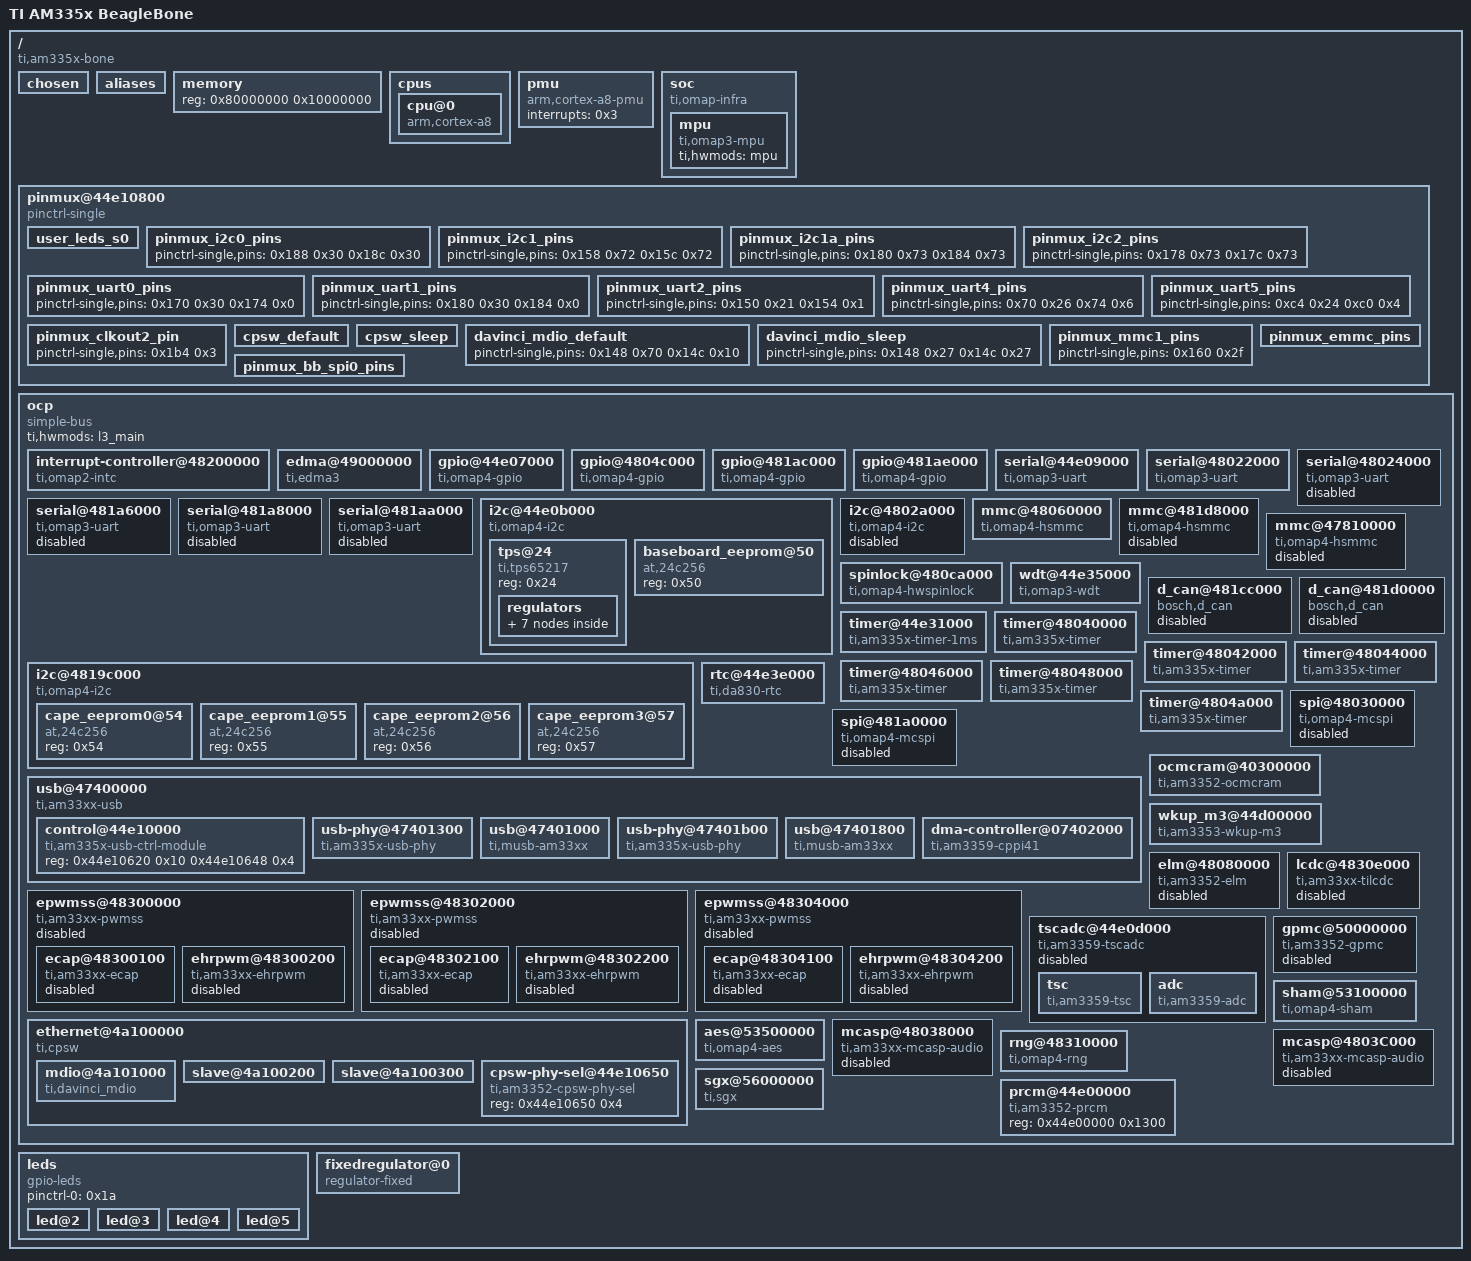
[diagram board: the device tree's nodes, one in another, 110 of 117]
/dts-v1/;

/ {
	#address-cells = <0x1>;
	#size-cells = <0x1>;
	compatible = "ti,am335x-bone", "ti,am33xx";
	interrupt-parent = <0x1>;
	model = "TI AM335x BeagleBone";

	chosen {
	};

	aliases {
		i2c0 = "/ocp/i2c@44e0b000";
		i2c1 = "/ocp/i2c@4802a000";
		i2c2 = "/ocp/i2c@4819c000";
		serial0 = "/ocp/serial@44e09000";
		serial1 = "/ocp/serial@48022000";
		serial2 = "/ocp/serial@48024000";
		serial3 = "/ocp/serial@481a6000";
		serial4 = "/ocp/serial@481a8000";
		serial5 = "/ocp/serial@481aa000";
		d_can0 = "/ocp/d_can@481cc000";
		d_can1 = "/ocp/d_can@481d0000";
		usb0 = "/ocp/usb@47400000/usb@47401000";
		usb1 = "/ocp/usb@47400000/usb@47401800";
		phy0 = "/ocp/usb@47400000/usb-phy@47401300";
		phy1 = "/ocp/usb@47400000/usb-phy@47401b00";
		ethernet0 = "/ocp/ethernet@4a100000/slave@4a100200";
		ethernet1 = "/ocp/ethernet@4a100000/slave@4a100300";
	};

	memory {
		device_type = "memory";
		reg = <0x80000000 0x10000000>;
	};

	cpus {
		#address-cells = <0x1>;
		#size-cells = <0x0>;

		cpu@0 {
			compatible = "arm,cortex-a8";
			device_type = "cpu";
			reg = <0x0>;
			operating-points = <0xafc80 0x139b88 0x927c0 0x12b128 0x7a120 0x112a88 0x43238 0x112a88>;
			voltage-tolerance = <0x2>;
			clock-latency = <0x493e0>;
			cpu0-supply = <0x2>;
		};
	};

	pmu {
		compatible = "arm,cortex-a8-pmu";
		interrupts = <0x3>;
	};

	soc {
		compatible = "ti,omap-infra";

		mpu {
			compatible = "ti,omap3-mpu";
			ti,hwmods = "mpu";
		};
	};

	pinmux@44e10800 {
		compatible = "pinctrl-single";
		reg = <0x44e10800 0x238>;
		#address-cells = <0x1>;
		#size-cells = <0x0>;
		pinctrl-single,register-width = <0x20>;
		pinctrl-single,function-mask = <0x7f>;
		pinctrl-names = "default";
		pinctrl-0 = <0x3>;

		user_leds_s0 {
			pinctrl-single,pins = <0x54 0x7 0x58 0x17 0x5c 0x7 0x60 0x17>;
			linux,phandle = <0x1a>;
			phandle = <0x1a>;
		};

		pinmux_i2c0_pins {
			pinctrl-single,pins = <0x188 0x30 0x18c 0x30>;
			linux,phandle = <0x9>;
			phandle = <0x9>;
		};

		pinmux_i2c1_pins {
			pinctrl-single,pins = <0x158 0x72 0x15c 0x72>;
			linux,phandle = <0xa>;
			phandle = <0xa>;
		};

		pinmux_i2c1a_pins {
			pinctrl-single,pins = <0x180 0x73 0x184 0x73>;
		};

		pinmux_i2c2_pins {
			pinctrl-single,pins = <0x178 0x73 0x17c 0x73>;
			linux,phandle = <0xb>;
			phandle = <0xb>;
		};

		pinmux_uart0_pins {
			pinctrl-single,pins = <0x170 0x30 0x174 0x0>;
			linux,phandle = <0x4>;
			phandle = <0x4>;
		};

		pinmux_uart1_pins {
			pinctrl-single,pins = <0x180 0x30 0x184 0x0>;
			linux,phandle = <0x5>;
			phandle = <0x5>;
		};

		pinmux_uart2_pins {
			pinctrl-single,pins = <0x150 0x21 0x154 0x1>;
			linux,phandle = <0x6>;
			phandle = <0x6>;
		};

		pinmux_uart4_pins {
			pinctrl-single,pins = <0x70 0x26 0x74 0x6>;
			linux,phandle = <0x7>;
			phandle = <0x7>;
		};

		pinmux_uart5_pins {
			pinctrl-single,pins = <0xc4 0x24 0xc0 0x4>;
			linux,phandle = <0x8>;
			phandle = <0x8>;
		};

		pinmux_clkout2_pin {
			pinctrl-single,pins = <0x1b4 0x3>;
			linux,phandle = <0x3>;
			phandle = <0x3>;
		};

		cpsw_default {
			pinctrl-single,pins = <0x110 0x30 0x114 0x0 0x118 0x30 0x11c 0x0 0x120 0x0 0x124 0x0 0x128 0x0 0x12c 0x30 0x130 0x30 0x134 0x30 0x138 0x30 0x13c 0x30 0x140 0x30>;
			linux,phandle = <0x14>;
			phandle = <0x14>;
		};

		cpsw_sleep {
			pinctrl-single,pins = <0x110 0x27 0x114 0x27 0x118 0x27 0x11c 0x27 0x120 0x27 0x124 0x27 0x128 0x27 0x12c 0x27 0x130 0x27 0x134 0x27 0x138 0x27 0x13c 0x27 0x140 0x27>;
			linux,phandle = <0x15>;
			phandle = <0x15>;
		};

		davinci_mdio_default {
			pinctrl-single,pins = <0x148 0x70 0x14c 0x10>;
			linux,phandle = <0x16>;
			phandle = <0x16>;
		};

		davinci_mdio_sleep {
			pinctrl-single,pins = <0x148 0x27 0x14c 0x27>;
			linux,phandle = <0x17>;
			phandle = <0x17>;
		};

		pinmux_mmc1_pins {
			pinctrl-single,pins = <0x160 0x2f>;
			linux,phandle = <0xd>;
			phandle = <0xd>;
		};

		pinmux_emmc_pins {
			pinctrl-single,pins = <0x80 0x32 0x84 0x32 0x0 0x31 0x4 0x31 0x8 0x31 0xc 0x31 0x10 0x31 0x14 0x31 0x18 0x31 0x1c 0x31>;
		};

		pinmux_bb_spi0_pins {
			pinctrl-single,pins = <0x150 0x30 0x154 0x30 0x158 0x10 0x15c 0x10>;
		};
	};

	ocp {
		compatible = "simple-bus";
		#address-cells = <0x1>;
		#size-cells = <0x1>;
		ranges;
		ti,hwmods = "l3_main";

		interrupt-controller@48200000 {
			compatible = "ti,omap2-intc";
			interrupt-controller;
			#interrupt-cells = <0x1>;
			ti,intc-size = <0x80>;
			reg = <0x48200000 0x1000>;
			linux,phandle = <0x1>;
			phandle = <0x1>;
		};

		edma@49000000 {
			compatible = "ti,edma3";
			ti,hwmods = "tpcc", "tptc0", "tptc1", "tptc2";
			reg = <0x49000000 0x10000 0x44e10f90 0x10>;
			interrupts = <0xc 0xd 0xe>;
			#dma-cells = <0x1>;
			dma-channels = <0x40>;
			ti,edma-regions = <0x4>;
			ti,edma-slots = <0x100>;
			linux,phandle = <0xc>;
			phandle = <0xc>;
		};

		gpio@44e07000 {
			compatible = "ti,omap4-gpio";
			ti,hwmods = "gpio1";
			gpio-controller;
			#gpio-cells = <0x2>;
			interrupt-controller;
			#interrupt-cells = <0x2>;
			reg = <0x44e07000 0x1000>;
			interrupts = <0x60>;
			linux,phandle = <0xe>;
			phandle = <0xe>;
		};

		gpio@4804c000 {
			compatible = "ti,omap4-gpio";
			ti,hwmods = "gpio2";
			gpio-controller;
			#gpio-cells = <0x2>;
			interrupt-controller;
			#interrupt-cells = <0x2>;
			reg = <0x4804c000 0x1000>;
			interrupts = <0x62>;
			linux,phandle = <0x1b>;
			phandle = <0x1b>;
		};

		gpio@481ac000 {
			compatible = "ti,omap4-gpio";
			ti,hwmods = "gpio3";
			gpio-controller;
			#gpio-cells = <0x2>;
			interrupt-controller;
			#interrupt-cells = <0x2>;
			reg = <0x481ac000 0x1000>;
			interrupts = <0x20>;
		};

		gpio@481ae000 {
			compatible = "ti,omap4-gpio";
			ti,hwmods = "gpio4";
			gpio-controller;
			#gpio-cells = <0x2>;
			interrupt-controller;
			#interrupt-cells = <0x2>;
			reg = <0x481ae000 0x1000>;
			interrupts = <0x3e>;
		};

		serial@44e09000 {
			compatible = "ti,omap3-uart";
			ti,hwmods = "uart1";
			clock-frequency = <0x2dc6c00>;
			reg = <0x44e09000 0x2000>;
			interrupts = <0x48>;
			status = "okay";
			pinctrl-names = "default";
			pinctrl-0 = <0x4>;
		};

		serial@48022000 {
			compatible = "ti,omap3-uart";
			ti,hwmods = "uart2";
			clock-frequency = <0x2dc6c00>;
			reg = <0x48022000 0x2000>;
			interrupts = <0x49>;
			status = "okay";
			pinctrl-names = "default";
			pinctrl-0 = <0x5>;
		};

		serial@48024000 {
			compatible = "ti,omap3-uart";
			ti,hwmods = "uart3";
			clock-frequency = <0x2dc6c00>;
			reg = <0x48024000 0x2000>;
			interrupts = <0x4a>;
			status = "disabled";
			//status = "okay";
			//pinctrl-names = "default";
			//pinctrl-0 = <0x6>;
		};

		serial@481a6000 {
			compatible = "ti,omap3-uart";
			ti,hwmods = "uart4";
			clock-frequency = <0x2dc6c00>;
			reg = <0x481a6000 0x2000>;
			interrupts = <0x2c>;
			status = "disabled";
		};

		serial@481a8000 {
			compatible = "ti,omap3-uart";
			ti,hwmods = "uart5";
			clock-frequency = <0x2dc6c00>;
			reg = <0x481a8000 0x2000>;
			interrupts = <0x2d>;
			status = "disabled";
			//status = "okay";
			//pinctrl-names = "default";
			//pinctrl-0 = <0x7>;
		};

		serial@481aa000 {
			compatible = "ti,omap3-uart";
			ti,hwmods = "uart6";
			clock-frequency = <0x2dc6c00>;
			reg = <0x481aa000 0x2000>;
			interrupts = <0x2e>;
			status = "disabled";
			//status = "okay";
			//pinctrl-names = "default";
			//pinctrl-0 = <0x8>;
		};

		i2c@44e0b000 {
			compatible = "ti,omap4-i2c";
			#address-cells = <0x1>;
			#size-cells = <0x0>;
			ti,hwmods = "i2c1";
			reg = <0x44e0b000 0x1000>;
			interrupts = <0x46>;
			status = "okay";
			pinctrl-names = "default";
			pinctrl-0 = <0x9>;
			clock-frequency = <0x61a80>;

			tps@24 {
				reg = <0x24>;
				compatible = "ti,tps65217";

				regulators {
					#address-cells = <0x1>;
					#size-cells = <0x0>;

					regulator@0 {
						reg = <0x0>;
						regulator-compatible = "dcdc1";
						regulator-always-on;
					};

					regulator@1 {
						reg = <0x1>;
						regulator-compatible = "dcdc2";
						regulator-name = "vdd_mpu";
						regulator-min-microvolt = <0xe1d48>;
						regulator-max-microvolt = <0x1437c8>;
						regulator-boot-on;
						regulator-always-on;
						linux,phandle = <0x2>;
						phandle = <0x2>;
					};

					regulator@2 {
						reg = <0x2>;
						regulator-compatible = "dcdc3";
						regulator-name = "vdd_core";
						regulator-min-microvolt = <0xe1d48>;
						regulator-max-microvolt = <0x118c30>;
						regulator-boot-on;
						regulator-always-on;
					};

					regulator@3 {
						reg = <0x3>;
						regulator-compatible = "ldo1";
						regulator-always-on;
					};

					regulator@4 {
						reg = <0x4>;
						regulator-compatible = "ldo2";
						regulator-always-on;
					};

					regulator@5 {
						reg = <0x5>;
						regulator-compatible = "ldo3";
						regulator-always-on;
						regulator-min-microvolt = <0x1b7740>;
						regulator-max-microvolt = <0x325aa0>;
						linux,phandle = <0xf>;
						phandle = <0xf>;
					};

					regulator@6 {
						reg = <0x6>;
						regulator-compatible = "ldo4";
						regulator-always-on;
					};
				};
			};

			baseboard_eeprom@50 {
				compatible = "at,24c256";
				reg = <0x50>;
			};
		};

		i2c@4802a000 {
			compatible = "ti,omap4-i2c";
			#address-cells = <0x1>;
			#size-cells = <0x0>;
			ti,hwmods = "i2c2";
			reg = <0x4802a000 0x1000>;
			interrupts = <0x47>;
			status = "disabled";
			//status = "okay";
			//pinctrl-names = "default";
			//pinctrl-0 = <0xa>;
			//clock-frequency = <0x186a0>;
		};

		i2c@4819c000 {
			compatible = "ti,omap4-i2c";
			#address-cells = <0x1>;
			#size-cells = <0x0>;
			ti,hwmods = "i2c3";
			reg = <0x4819c000 0x1000>;
			interrupts = <0x1e>;
			status = "okay";
			pinctrl-names = "default";
			pinctrl-0 = <0xb>;
			clock-frequency = <0x186a0>;

			cape_eeprom0@54 {
				compatible = "at,24c256";
				reg = <0x54>;
			};

			cape_eeprom1@55 {
				compatible = "at,24c256";
				reg = <0x55>;
			};

			cape_eeprom2@56 {
				compatible = "at,24c256";
				reg = <0x56>;
			};

			cape_eeprom3@57 {
				compatible = "at,24c256";
				reg = <0x57>;
			};
		};

		mmc@48060000 {
			compatible = "ti,omap4-hsmmc";
			ti,hwmods = "mmc1";
			ti,dual-volt;
			ti,needs-special-reset;
			ti,needs-special-hs-handling;
			dmas = <0xc 0x18 0xc 0x19>;
			dma-names = "tx", "rx";
			interrupts = <0x40>;
			interrupt-parent = <0x1>;
			reg = <0x48060000 0x1000>;
			status = "okay";
			bus-width = <0x4>;
			pinctrl-names = "default";
			pinctrl-0 = <0xd>;
			cd-gpios = <0xe 0x6 0x0>;
			cd-inverted;
			vmmc-supply = <0xf>;
		};

		mmc@481d8000 {
			compatible = "ti,omap4-hsmmc";
			ti,hwmods = "mmc2";
			ti,needs-special-reset;
			dmas = <0xc 0x2 0xc 0x3>;
			dma-names = "tx", "rx";
			interrupts = <0x1c>;
			interrupt-parent = <0x1>;
			reg = <0x481d8000 0x1000>;
			status = "disabled";
		};

		mmc@47810000 {
			compatible = "ti,omap4-hsmmc";
			ti,hwmods = "mmc3";
			ti,needs-special-reset;
			interrupts = <0x1d>;
			interrupt-parent = <0x1>;
			reg = <0x47810000 0x1000>;
			status = "disabled";
		};

		spinlock@480ca000 {
			compatible = "ti,omap4-hwspinlock";
			reg = <0x480ca000 0x1000>;
			ti,hwmods = "spinlock";
		};

		wdt@44e35000 {
			compatible = "ti,omap3-wdt";
			ti,hwmods = "wd_timer2";
			reg = <0x44e35000 0x1000>;
			interrupts = <0x5b>;
		};

		d_can@481cc000 {
			compatible = "bosch,d_can";
			ti,hwmods = "d_can0";
			reg = <0x481cc000 0x2000 0x44e10644 0x4>;
			interrupts = <0x34>;
			status = "disabled";
		};

		d_can@481d0000 {
			compatible = "bosch,d_can";
			ti,hwmods = "d_can1";
			reg = <0x481d0000 0x2000 0x44e10644 0x4>;
			interrupts = <0x37>;
			status = "disabled";
		};

		timer@44e31000 {
			compatible = "ti,am335x-timer-1ms";
			reg = <0x44e31000 0x400>;
			interrupts = <0x43>;
			ti,hwmods = "timer1";
			ti,timer-alwon;
		};

		timer@48040000 {
			compatible = "ti,am335x-timer";
			reg = <0x48040000 0x400>;
			interrupts = <0x44>;
			ti,hwmods = "timer2";
		};

		timer@48042000 {
			compatible = "ti,am335x-timer";
			reg = <0x48042000 0x400>;
			interrupts = <0x45>;
			ti,hwmods = "timer3";
		};

		timer@48044000 {
			compatible = "ti,am335x-timer";
			reg = <0x48044000 0x400>;
			interrupts = <0x5c>;
			ti,hwmods = "timer4";
			ti,timer-pwm;
		};

		timer@48046000 {
			compatible = "ti,am335x-timer";
			reg = <0x48046000 0x400>;
			interrupts = <0x5d>;
			ti,hwmods = "timer5";
			ti,timer-pwm;
		};

		timer@48048000 {
			compatible = "ti,am335x-timer";
			reg = <0x48048000 0x400>;
			interrupts = <0x5e>;
			ti,hwmods = "timer6";
			ti,timer-pwm;
		};

		timer@4804a000 {
			compatible = "ti,am335x-timer";
			reg = <0x4804a000 0x400>;
			interrupts = <0x5f>;
			ti,hwmods = "timer7";
			ti,timer-pwm;
		};

		rtc@44e3e000 {
			compatible = "ti,da830-rtc";
			reg = <0x44e3e000 0x1000>;
			interrupts = <0x4b 0x4c>;
			ti,hwmods = "rtc";
		};

		spi@48030000 {
			compatible = "ti,omap4-mcspi";
			#address-cells = <0x1>;
			#size-cells = <0x0>;
			reg = <0x48030000 0x400>;
			interrupts = <0x41>;
			ti,spi-num-cs = <0x2>;
			ti,hwmods = "spi0";
			dmas = <0xc 0x10 0xc 0x11 0xc 0x12 0xc 0x13>;
			dma-names = "tx0", "rx0", "tx1", "rx1";
			status = "disabled";
		};

		spi@481a0000 {
			compatible = "ti,omap4-mcspi";
			#address-cells = <0x1>;
			#size-cells = <0x0>;
			reg = <0x481a0000 0x400>;
			interrupts = <0x7d>;
			ti,spi-num-cs = <0x2>;
			ti,hwmods = "spi1";
			dmas = <0xc 0x2a 0xc 0x2b 0xc 0x2c 0xc 0x2d>;
			dma-names = "tx0", "rx0", "tx1", "rx1";
			status = "disabled";
		};

		usb@47400000 {
			compatible = "ti,am33xx-usb";
			reg = <0x47400000 0x1000>;
			ranges;
			#address-cells = <0x1>;
			#size-cells = <0x1>;
			ti,hwmods = "usb_otg_hs";
			status = "okay";

			control@44e10000 {
				compatible = "ti,am335x-usb-ctrl-module";
				reg = <0x44e10620 0x10 0x44e10648 0x4>;
				reg-names = "phy_ctrl", "wakeup";
				status = "okay";
				linux,phandle = <0x10>;
				phandle = <0x10>;
			};

			usb-phy@47401300 {
				compatible = "ti,am335x-usb-phy";
				reg = <0x47401300 0x100>;
				reg-names = "phy";
				status = "okay";
				ti,ctrl_mod = <0x10>;
				linux,phandle = <0x11>;
				phandle = <0x11>;
			};

			usb@47401000 {
				compatible = "ti,musb-am33xx";
				status = "okay";
				reg = <0x47401400 0x400 0x47401000 0x200>;
				reg-names = "mc", "control";
				interrupts = <0x12>;
				interrupt-names = "mc";
				dr_mode = "otg";
				mentor,multipoint = <0x1>;
				mentor,num-eps = <0x10>;
				mentor,ram-bits = <0xc>;
				mentor,power = <0x1f4>;
				phys = <0x11>;
				dmas = <0x12 0x0 0x0 0x12 0x1 0x0 0x12 0x2 0x0 0x12 0x3 0x0 0x12 0x4 0x0 0x12 0x5 0x0 0x12 0x6 0x0 0x12 0x7 0x0 0x12 0x8 0x0 0x12 0x9 0x0 0x12 0xa 0x0 0x12 0xb 0x0 0x12 0xc 0x0 0x12 0xd 0x0 0x12 0xe 0x0 0x12 0x0 0x1 0x12 0x1 0x1 0x12 0x2 0x1 0x12 0x3 0x1 0x12 0x4 0x1 0x12 0x5 0x1 0x12 0x6 0x1 0x12 0x7 0x1 0x12 0x8 0x1 0x12 0x9 0x1 0x12 0xa 0x1 0x12 0xb 0x1 0x12 0xc 0x1 0x12 0xd 0x1 0x12 0xe 0x1>;
				dma-names = "rx1", "rx2", "rx3", "rx4", "rx5", "rx6", "rx7", "rx8", "rx9", "rx10", "rx11", "rx12", "rx13", "rx14", "rx15", "tx1", "tx2", "tx3", "tx4", "tx5", "tx6", "tx7", "tx8", "tx9", "tx10", "tx11", "tx12", "tx13", "tx14", "tx15";
			};

			usb-phy@47401b00 {
				compatible = "ti,am335x-usb-phy";
				reg = <0x47401b00 0x100>;
				reg-names = "phy";
				status = "okay";
				ti,ctrl_mod = <0x10>;
				linux,phandle = <0x13>;
				phandle = <0x13>;
			};

			usb@47401800 {
				compatible = "ti,musb-am33xx";
				status = "okay";
				reg = <0x47401c00 0x400 0x47401800 0x200>;
				reg-names = "mc", "control";
				interrupts = <0x13>;
				interrupt-names = "mc";
				dr_mode = "host";
				mentor,multipoint = <0x1>;
				mentor,num-eps = <0x10>;
				mentor,ram-bits = <0xc>;
				mentor,power = <0x1f4>;
				phys = <0x13>;
				dmas = <0x12 0xf 0x0 0x12 0x10 0x0 0x12 0x11 0x0 0x12 0x12 0x0 0x12 0x13 0x0 0x12 0x14 0x0 0x12 0x15 0x0 0x12 0x16 0x0 0x12 0x17 0x0 0x12 0x18 0x0 0x12 0x19 0x0 0x12 0x1a 0x0 0x12 0x1b 0x0 0x12 0x1c 0x0 0x12 0x1d 0x0 0x12 0xf 0x1 0x12 0x10 0x1 0x12 0x11 0x1 0x12 0x12 0x1 0x12 0x13 0x1 0x12 0x14 0x1 0x12 0x15 0x1 0x12 0x16 0x1 0x12 0x17 0x1 0x12 0x18 0x1 0x12 0x19 0x1 0x12 0x1a 0x1 0x12 0x1b 0x1 0x12 0x1c 0x1 0x12 0x1d 0x1>;
				dma-names = "rx1", "rx2", "rx3", "rx4", "rx5", "rx6", "rx7", "rx8", "rx9", "rx10", "rx11", "rx12", "rx13", "rx14", "rx15", "tx1", "tx2", "tx3", "tx4", "tx5", "tx6", "tx7", "tx8", "tx9", "tx10", "tx11", "tx12", "tx13", "tx14", "tx15";
			};

			dma-controller@07402000 {
				compatible = "ti,am3359-cppi41";
				reg = <0x47400000 0x1000 0x47402000 0x1000 0x47403000 0x1000 0x47404000 0x4000>;
				reg-names = "glue", "controller", "scheduler", "queuemgr";
				interrupts = <0x11>;
				interrupt-names = "glue";
				#dma-cells = <0x2>;
				#dma-channels = <0x1e>;
				#dma-requests = <0x100>;
				status = "okay";
				linux,phandle = <0x12>;
				phandle = <0x12>;
			};
		};

		epwmss@48300000 {
			compatible = "ti,am33xx-pwmss";
			reg = <0x48300000 0x10>;
			ti,hwmods = "epwmss0";
			#address-cells = <0x1>;
			#size-cells = <0x1>;
			status = "disabled";
			ranges = <0x48300100 0x48300100 0x80 0x48300180 0x48300180 0x80 0x48300200 0x48300200 0x80>;

			ecap@48300100 {
				compatible = "ti,am33xx-ecap";
				#pwm-cells = <0x3>;
				reg = <0x48300100 0x80>;
				ti,hwmods = "ecap0";
				status = "disabled";
			};

			ehrpwm@48300200 {
				compatible = "ti,am33xx-ehrpwm";
				#pwm-cells = <0x3>;
				reg = <0x48300200 0x80>;
				ti,hwmods = "ehrpwm0";
				status = "disabled";
			};
		};

		epwmss@48302000 {
			compatible = "ti,am33xx-pwmss";
			reg = <0x48302000 0x10>;
			ti,hwmods = "epwmss1";
			#address-cells = <0x1>;
			#size-cells = <0x1>;
			status = "disabled";
			ranges = <0x48302100 0x48302100 0x80 0x48302180 0x48302180 0x80 0x48302200 0x48302200 0x80>;

			ecap@48302100 {
				compatible = "ti,am33xx-ecap";
				#pwm-cells = <0x3>;
				reg = <0x48302100 0x80>;
				ti,hwmods = "ecap1";
				status = "disabled";
			};

			ehrpwm@48302200 {
				compatible = "ti,am33xx-ehrpwm";
				#pwm-cells = <0x3>;
				reg = <0x48302200 0x80>;
				ti,hwmods = "ehrpwm1";
				status = "disabled";
			};
		};

		epwmss@48304000 {
			compatible = "ti,am33xx-pwmss";
			reg = <0x48304000 0x10>;
			ti,hwmods = "epwmss2";
			#address-cells = <0x1>;
			#size-cells = <0x1>;
			status = "disabled";
			ranges = <0x48304100 0x48304100 0x80 0x48304180 0x48304180 0x80 0x48304200 0x48304200 0x80>;

			ecap@48304100 {
				compatible = "ti,am33xx-ecap";
				#pwm-cells = <0x3>;
				reg = <0x48304100 0x80>;
				ti,hwmods = "ecap2";
				status = "disabled";
			};

			ehrpwm@48304200 {
				compatible = "ti,am33xx-ehrpwm";
				#pwm-cells = <0x3>;
				reg = <0x48304200 0x80>;
				ti,hwmods = "ehrpwm2";
				status = "disabled";
			};
		};

		ethernet@4a100000 {
			compatible = "ti,cpsw";
			ti,hwmods = "cpgmac0";
			cpdma_channels = <0x8>;
			ale_entries = <0x400>;
			bd_ram_size = <0x2000>;
			no_bd_ram = <0x0>;
			rx_descs = <0x40>;
			mac_control = <0x20>;
			slaves = <0x2>;
			active_slave = <0x0>;
			cpts_clock_mult = <0x80000000>;
			cpts_clock_shift = <0x1d>;
			reg = <0x4a100000 0x800 0x4a101200 0x100>;
			#address-cells = <0x1>;
			#size-cells = <0x1>;
			interrupt-parent = <0x1>;
			interrupts = <0x28 0x29 0x2a 0x2b>;
			ranges;
			pinctrl-names = "default", "sleep";
			pinctrl-0 = <0x14>;
			pinctrl-1 = <0x15>;

			mdio@4a101000 {
				compatible = "ti,davinci_mdio";
				#address-cells = <0x1>;
				#size-cells = <0x0>;
				ti,hwmods = "davinci_mdio";
				bus_freq = <0xf4240>;
				reg = <0x4a101000 0x100>;
				pinctrl-names = "default", "sleep";
				pinctrl-0 = <0x16>;
				pinctrl-1 = <0x17>;
				linux,phandle = <0x18>;
				phandle = <0x18>;
			};

			slave@4a100200 {
				mac-address = [00 00 00 00 00 00];
				phy_id = <0x18 0x0>;
				phy-mode = "mii";
			};

			slave@4a100300 {
				mac-address = [00 00 00 00 00 00];
				phy_id = <0x18 0x1>;
				phy-mode = "mii";
			};

			cpsw-phy-sel@44e10650 {
				compatible = "ti,am3352-cpsw-phy-sel";
				reg = <0x44e10650 0x4>;
				reg-names = "gmii-sel";
			};
		};

		ocmcram@40300000 {
			compatible = "ti,am3352-ocmcram";
			reg = <0x40300000 0x10000>;
			ti,hwmods = "ocmcram";
		};

		wkup_m3@44d00000 {
			compatible = "ti,am3353-wkup-m3";
			reg = <0x44d00000 0x4000 0x44d80000 0x2000>;
			ti,hwmods = "wkup_m3";
			ti,no-reset-on-init;
		};

		elm@48080000 {
			compatible = "ti,am3352-elm";
			reg = <0x48080000 0x2000>;
			interrupts = <0x4>;
			ti,hwmods = "elm";
			status = "disabled";
		};

		lcdc@4830e000 {
			compatible = "ti,am33xx-tilcdc";
			reg = <0x4830e000 0x1000>;
			interrupt-parent = <0x1>;
			interrupts = <0x24>;
			ti,hwmods = "lcdc";
			status = "disabled";
		};

		tscadc@44e0d000 {
			compatible = "ti,am3359-tscadc";
			reg = <0x44e0d000 0x1000>;
			interrupt-parent = <0x1>;
			interrupts = <0x10>;
			ti,hwmods = "adc_tsc";
			status = "disabled";

			tsc {
				compatible = "ti,am3359-tsc";
			};

			adc {
				#io-channel-cells = <0x1>;
				compatible = "ti,am3359-adc";
			};
		};

		gpmc@50000000 {
			compatible = "ti,am3352-gpmc";
			ti,hwmods = "gpmc";
			ti,no-idle-on-init;
			reg = <0x50000000 0x2000>;
			interrupts = <0x64>;
			gpmc,num-cs = <0x7>;
			gpmc,num-waitpins = <0x2>;
			#address-cells = <0x2>;
			#size-cells = <0x1>;
			status = "disabled";
		};

		sham@53100000 {
			compatible = "ti,omap4-sham";
			ti,hwmods = "sham";
			reg = <0x53100000 0x200>;
			interrupts = <0x6d>;
			dmas = <0xc 0x24>;
			dma-names = "rx";
			status = "okay";
		};

		aes@53500000 {
			compatible = "ti,omap4-aes";
			ti,hwmods = "aes";
			reg = <0x53500000 0xa0>;
			interrupts = <0x67>;
			dmas = <0xc 0x6 0xc 0x5>;
			dma-names = "tx", "rx";
			status = "okay";
		};

		mcasp@48038000 {
			compatible = "ti,am33xx-mcasp-audio";
			ti,hwmods = "mcasp0";
			reg = <0x48038000 0x2000 0x46000000 0x400000>;
			reg-names = "mpu", "dat";
			interrupts = <0x50 0x51>;
			interrupts-names = "tx", "rx";
			status = "disabled";
			dmas = <0xc 0x8 0xc 0x9>;
			dma-names = "tx", "rx";
		};

		mcasp@4803C000 {
			compatible = "ti,am33xx-mcasp-audio";
			ti,hwmods = "mcasp1";
			reg = <0x4803c000 0x2000 0x46400000 0x400000>;
			reg-names = "mpu", "dat";
			interrupts = <0x52 0x53>;
			interrupts-names = "tx", "rx";
			status = "disabled";
			dmas = <0xc 0xa 0xc 0xb>;
			dma-names = "tx", "rx";
		};

		rng@48310000 {
			compatible = "ti,omap4-rng";
			ti,hwmods = "rng";
			reg = <0x48310000 0x2000>;
			interrupts = <0x6f>;
		};

		prcm@44e00000 {
			compatible = "ti,am3352-prcm";
			reg = <0x44e00000 0x1300>;
			#reset-cells = <0x1>;
			linux,phandle = <0x19>;
			phandle = <0x19>;
		};

		sgx@56000000 {
			compatible = "ti,sgx";
			ti,hwmods = "gfx";
			reg = <0x56000000 0x1000000>;
			interrupts = <0x25>;
			resets = <0x19 0x0>;
		};
	};

	leds {
		pinctrl-names = "default";
		pinctrl-0 = <0x1a>;
		compatible = "gpio-leds";

		led@2 {
			label = "beaglebone:green:heartbeat";
			gpios = <0x1b 0x15 0x0>;
			linux,default-trigger = "heartbeat";
			default-state = "off";
		};

		led@3 {
			label = "beaglebone:green:mmc0";
			gpios = <0x1b 0x16 0x0>;
			linux,default-trigger = "mmc0";
			default-state = "off";
		};

		led@4 {
			label = "beaglebone:green:usr2";
			gpios = <0x1b 0x17 0x0>;
			linux,default-trigger = "cpu0";
			default-state = "off";
		};

		led@5 {
			label = "beaglebone:green:usr3";
			gpios = <0x1b 0x18 0x0>;
			linux,default-trigger = "mmc1";
			default-state = "off";
		};
	};

	fixedregulator@0 {
		compatible = "regulator-fixed";
		regulator-name = "vmmcsd_fixed";
		regulator-min-microvolt = <0x325aa0>;
		regulator-max-microvolt = <0x325aa0>;
	};
};
